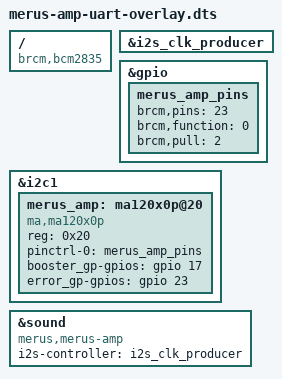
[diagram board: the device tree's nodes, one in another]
// Infineon Merus MA120x0P amplifier (InnoMaker HiFi AMP Pro Mini) without the
// enable (GPIO14) and mute (GPIO15) lines of the stock merus-amp overlay, so
// that GPIO14/15 stay free for the UART to the ESP32 light controller.
// Same I2S/I2C wiring and the same card ("snd_rpi_merus_amp") otherwise.
// Only valid if the HAT does not rely on those two lines (the amplifier then
// stays enabled and unmuted by its own pull resistors).
/dts-v1/;
/plugin/;
#include <dt-bindings/pinctrl/bcm2835.h>
#include <dt-bindings/gpio/gpio.h>

/ {
	compatible = "brcm,bcm2835";

	fragment@0 {
		target = <&i2s_clk_producer>;
		__overlay__ {
			status = "okay";
		};
	};

	fragment@1 {
		target = <&gpio>;
		__overlay__ {
			merus_amp_pins: merus_amp_pins {
				brcm,pins = <23>;
				brcm,function = <0>;
				brcm,pull = <2>;
			};
		};
	};

	fragment@2 {
		target = <&i2c1>;
		__overlay__ {
			#address-cells = <1>;
			#size-cells = <0>;
			status = "okay";

			merus_amp: ma120x0p@20 {
				#sound-dai-cells = <0>;
				compatible = "ma,ma120x0p";
				reg = <0x20>;
				status = "okay";
				pinctrl-names = "default";
				pinctrl-0 = <&merus_amp_pins>;
				booster_gp-gpios = <&gpio 17 GPIO_ACTIVE_HIGH>;
				error_gp-gpios = <&gpio 23 GPIO_ACTIVE_HIGH>;
			};
		};
	};

	fragment@3 {
		target = <&sound>;
		__overlay__ {
			compatible = "merus,merus-amp";
			i2s-controller = <&i2s_clk_producer>;
			status = "okay";
		};
	};
};
